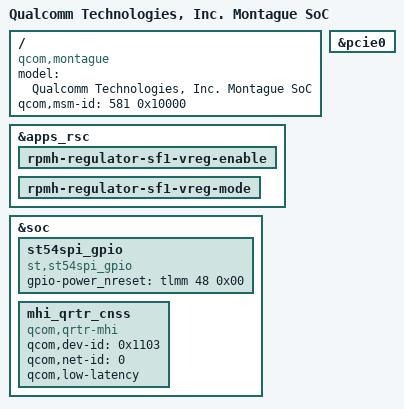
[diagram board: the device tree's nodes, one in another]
#include "ravelin.dtsi"

/ {
	model = "Qualcomm Technologies, Inc. Montague SoC";
	compatible = "qcom,montague";
	qcom,msm-id = <581 0x10000>;
};

&apps_rsc {
	rpmh-regulator-sf1-vreg-enable {
		status = "ok";
	};

	rpmh-regulator-sf1-vreg-mode {
		status = "ok";
	};
};

&soc {
	st54spi_gpio {
		status = "ok";
		compatible = "st,st54spi_gpio";
		/* gpio used as SE_nRESET */
		gpio-power_nreset = <&tlmm 48 0x00>;
	};

	mhi_qrtr_cnss {
		compatible = "qcom,qrtr-mhi";
		qcom,dev-id = <0x1103>;
		qcom,net-id = <0>;
		qcom,low-latency;
	};
};

&pcie0 {

/delete-property/ qcom,config-recovery;
/delete-property/ qcom,drv-supported;

};

